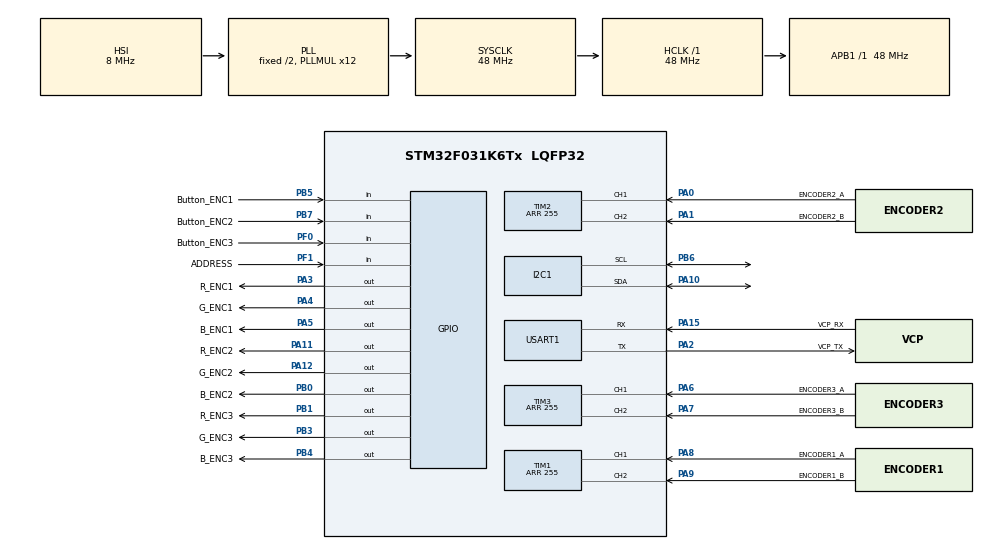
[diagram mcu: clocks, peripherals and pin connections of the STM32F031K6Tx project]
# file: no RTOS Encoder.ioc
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I2C1.Analog_Filter=I2C_ANALOGFILTER_DISABLE
I2C1.I2C_Fall_Time=10
I2C1.I2C_Rise_Time=10
I2C1.Timing=0x00201D2D
Mcu.Family=STM32F0
Mcu.Name=STM32F031K6Tx
Mcu.Package=LQFP32
NVIC.I2C1_IRQn=true\:0\:0\:false\:false\:true\:true\:true
NVIC.TIM14_IRQn=true\:0\:0\:false\:false\:true\:false\:true
NVIC.TimeBase=TIM14_IRQn
NVIC.TimeBaseIP=TIM14
PA0.GPIO_Label=ENCODER2_A
PA0.GPIO_PuPd=GPIO_PULLUP
PA0.Signal=S_TIM2_CH1_ETR
PA1.GPIO_Label=ENCODER2_B
PA1.GPIO_PuPd=GPIO_PULLUP
PA1.Signal=S_TIM2_CH2
PA10.Mode=I2C
PA10.Signal=I2C1_SDA
PA11.GPIO_Label=R_ENC2
PA11.Signal=GPIO_Output
PA12.GPIO_Label=G_ENC2
PA12.Signal=GPIO_Output
PA13.GPIO_Label=SWDIO
PA13.Mode=Serial_Wire
PA13.Signal=SYS_SWDIO
PA14.GPIO_Label=SWCLK
PA14.Mode=Serial_Wire
PA14.Signal=SYS_SWCLK
PA15.GPIO_Label=VCP_RX
PA15.Mode=Asynchronous
PA15.Signal=USART1_RX
PA2.GPIO_Label=VCP_TX
PA2.Mode=Asynchronous
PA2.Signal=USART1_TX
PA3.GPIO_Label=R_ENC1
PA3.Signal=GPIO_Output
PA4.GPIO_Label=G_ENC1
PA4.Signal=GPIO_Output
PA5.GPIO_Label=B_ENC1
PA5.Signal=GPIO_Output
PA6.GPIO_Label=ENCODER3_A
PA6.GPIO_PuPd=GPIO_PULLUP
PA6.Signal=S_TIM3_CH1
PA7.GPIO_Label=ENCODER3_B
PA7.GPIO_PuPd=GPIO_PULLUP
PA7.Signal=S_TIM3_CH2
PA8.GPIO_Label=ENCODER1_A
PA8.GPIO_PuPd=GPIO_PULLUP
PA8.Signal=S_TIM1_CH1
PA9.GPIO_Label=ENCODER1_B
PA9.GPIO_PuPd=GPIO_PULLUP
PA9.Signal=S_TIM1_CH2
PB0.GPIO_Label=B_ENC2
PB0.Signal=GPIO_Output
PB1.GPIO_Label=R_ENC3
PB1.Signal=GPIO_Output
PB3.GPIO_Label=G_ENC3
PB3.Signal=GPIO_Output
PB4.GPIO_Label=B_ENC3
PB4.Signal=GPIO_Output
PB5.GPIO_Label=Button_ENC1
PB5.Signal=GPIO_Input
PB6.Mode=I2C
PB6.Signal=I2C1_SCL
PB7.GPIO_Label=Button_ENC2
PB7.Signal=GPIO_Input
PF0-OSC_IN.GPIO_Label=Button_ENC3
PF0-OSC_IN.Signal=GPIO_Input
PF1-OSC_OUT.GPIO_Label=ADDRESS
PF1-OSC_OUT.Signal=GPIO_Input
ProjectManager.HeapSize=0x200
ProjectManager.StackSize=0x400
ProjectManager.TargetToolchain=SW4STM32
RCC.AHBFreq_Value=48000000
RCC.APB1Freq_Value=48000000
RCC.APB1TimFreq_Value=48000000
RCC.HCLKFreq_Value=48000000
RCC.PLLMUL=RCC_PLL_MUL12
RCC.SYSCLKFreq_VALUE=48000000
RCC.SYSCLKSource=RCC_SYSCLKSOURCE_PLLCLK
SH.S_TIM1_CH1.0=TIM1_CH1,Encoder_Interface
SH.S_TIM1_CH2.0=TIM1_CH2,Encoder_Interface
SH.S_TIM2_CH1_ETR.0=TIM2_CH1,Encoder_Interface
SH.S_TIM2_CH2.0=TIM2_CH2,Encoder_Interface
SH.S_TIM3_CH1.0=TIM3_CH1,Encoder_Interface
SH.S_TIM3_CH2.0=TIM3_CH2,Encoder_Interface
TIM1.EncoderMode=TIM_ENCODERMODE_TI12
TIM1.IC1Filter=0
TIM1.IC1Polarity=TIM_ICPOLARITY_FALLING
TIM1.IC2Filter=0
TIM1.IC2Polarity=TIM_ICPOLARITY_FALLING
TIM1.Period=255
TIM16.Period=10000
TIM16.Prescaler=48
TIM2.EncoderMode=TIM_ENCODERMODE_TI12
TIM2.IC1Filter=0
TIM2.IC1Polarity=TIM_ICPOLARITY_FALLING
TIM2.IC2Polarity=TIM_ICPOLARITY_FALLING
TIM2.Period=255
TIM3.IC1Filter=0
TIM3.IC1Polarity=TIM_ICPOLARITY_FALLING
TIM3.IC2Filter=0
TIM3.IC2Polarity=TIM_ICPOLARITY_FALLING
TIM3.Period=255
USART1.VirtualMode-Asynchronous=VM_ASYNC
VP_SYS_VS_tim14.Mode=TIM14
VP_TIM16_VS_ClockSourceINT.Mode=Enable_Timer
board=NUCLEO-F031K6

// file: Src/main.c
/* USER CODE BEGIN Header */
/**
  ******************************************************************************
  * @file           : main.c
  * @brief          : Main program body
  ******************************************************************************
  * @attention
  *
  * <h2><center>&copy; Copyright (c) 2019 STMicroelectronics.
  * All rights reserved.</center></h2>
  *
  * This software component is licensed by ST under BSD 3-Clause license,
  * the "License"; You may not use this file except in compliance with the
  * License. You may obtain a copy of the License at:
  *                        opensource.org/licenses/BSD-3-Clause
  *
  ******************************************************************************
  */
/* USER CODE END Header */

#include "main.h"

I2C_HandleTypeDef hi2c1;

TIM_HandleTypeDef htim1;
TIM_HandleTypeDef htim2;
TIM_HandleTypeDef htim3;
TIM_HandleTypeDef htim16;

UART_HandleTypeDef huart1;

void SystemClock_Config(void);
static void MX_GPIO_Init(void);
static void MX_I2C1_Init(void);
static void MX_TIM1_Init(void);
static void MX_TIM2_Init(void);
static void MX_TIM3_Init(void);
static void MX_USART1_UART_Init(void);
static void MX_TIM16_Init(void);

int main(void)
{

  /* MCU Configuration--------------------------------------------------------*/

  /* Reset of all peripherals, Initializes the Flash interface and the Systick. */
  HAL_Init();

  /* Configure the system clock */
  SystemClock_Config();

  /* Initialize all configured peripherals */
  MX_GPIO_Init();
  MX_I2C1_Init();
  MX_TIM1_Init();
  MX_TIM2_Init();
  MX_TIM3_Init();
  MX_USART1_UART_Init();
  MX_TIM16_Init();
  /* USER CODE BEGIN 2 */
  uint8_t aTxBuffer[] = "E";

  /* Buffer used for reception */
  uint8_t aRxBuffer[1];

  uint32_t Encoder_CODE;
  HAL_I2C_Slave_Receive_DMA(&hi2c1,aRxBuffer,1);
  HAL_I2C_Slave_Transmit_DMA(&hi2c1,aTxBuffer,1);
  /* USER CODE END 2 */

  /* Infinite loop */
  while (1)
  {

  }
}

void SystemClock_Config(void)
{
  RCC_OscInitTypeDef RCC_OscInitStruct = {0};
  RCC_ClkInitTypeDef RCC_ClkInitStruct = {0};
  RCC_PeriphCLKInitTypeDef PeriphClkInit = {0};

  /** Initializes the CPU, AHB and APB busses clocks
  */
  RCC_OscInitStruct.OscillatorType = RCC_OSCILLATORTYPE_HSI;
  RCC_OscInitStruct.HSIState = RCC_HSI_ON;
  RCC_OscInitStruct.HSICalibrationValue = RCC_HSICALIBRATION_DEFAULT;
  RCC_OscInitStruct.PLL.PLLState = RCC_PLL_ON;
  RCC_OscInitStruct.PLL.PLLSource = RCC_PLLSOURCE_HSI;
  RCC_OscInitStruct.PLL.PLLMUL = RCC_PLL_MUL12;
  RCC_OscInitStruct.PLL.PREDIV = RCC_PREDIV_DIV1;
  if (HAL_RCC_OscConfig(&RCC_OscInitStruct) != HAL_OK)
  {
    Error_Handler();
  }
  /** Initializes the CPU, AHB and APB busses clocks
  */
  RCC_ClkInitStruct.ClockType = RCC_CLOCKTYPE_HCLK|RCC_CLOCKTYPE_SYSCLK
                              |RCC_CLOCKTYPE_PCLK1;
  RCC_ClkInitStruct.SYSCLKSource = RCC_SYSCLKSOURCE_PLLCLK;
  RCC_ClkInitStruct.AHBCLKDivider = RCC_SYSCLK_DIV1;
  RCC_ClkInitStruct.APB1CLKDivider = RCC_HCLK_DIV1;

  if (HAL_RCC_ClockConfig(&RCC_ClkInitStruct, FLASH_LATENCY_1) != HAL_OK)
  {
    Error_Handler();
  }
  PeriphClkInit.PeriphClockSelection = RCC_PERIPHCLK_USART1|RCC_PERIPHCLK_I2C1;
  PeriphClkInit.Usart1ClockSelection = RCC_USART1CLKSOURCE_PCLK1;
  PeriphClkInit.I2c1ClockSelection = RCC_I2C1CLKSOURCE_HSI;
  if (HAL_RCCEx_PeriphCLKConfig(&PeriphClkInit) != HAL_OK)
  {
    Error_Handler();
  }
}

static void MX_I2C1_Init(void)
{

  hi2c1.Instance = I2C1;
  hi2c1.Init.Timing = 0x00201D2D;
  hi2c1.Init.OwnAddress1 = 0;
  hi2c1.Init.AddressingMode = I2C_ADDRESSINGMODE_7BIT;
  hi2c1.Init.DualAddressMode = I2C_DUALADDRESS_DISABLE;
  hi2c1.Init.OwnAddress2 = 0;
  hi2c1.Init.OwnAddress2Masks = I2C_OA2_NOMASK;
  hi2c1.Init.GeneralCallMode = I2C_GENERALCALL_DISABLE;
  hi2c1.Init.NoStretchMode = I2C_NOSTRETCH_DISABLE;
  if (HAL_I2C_Init(&hi2c1) != HAL_OK)
  {
    Error_Handler();
  }
  /** Configure Analogue filter
  */
  if (HAL_I2CEx_ConfigAnalogFilter(&hi2c1, I2C_ANALOGFILTER_DISABLE) != HAL_OK)
  {
    Error_Handler();
  }
  /** Configure Digital filter
  */
  if (HAL_I2CEx_ConfigDigitalFilter(&hi2c1, 0) != HAL_OK)
  {
    Error_Handler();
  }

}

static void MX_TIM1_Init(void)
{

  TIM_Encoder_InitTypeDef sConfig = {0};
  TIM_MasterConfigTypeDef sMasterConfig = {0};

  htim1.Instance = TIM1;
  htim1.Init.Prescaler = 0;
  htim1.Init.CounterMode = TIM_COUNTERMODE_UP;
  htim1.Init.Period = 255;
  htim1.Init.ClockDivision = TIM_CLOCKDIVISION_DIV1;
  htim1.Init.RepetitionCounter = 0;
  htim1.Init.AutoReloadPreload = TIM_AUTORELOAD_PRELOAD_DISABLE;
  sConfig.EncoderMode = TIM_ENCODERMODE_TI12;
  sConfig.IC1Polarity = TIM_ICPOLARITY_FALLING;
  sConfig.IC1Selection = TIM_ICSELECTION_DIRECTTI;
  sConfig.IC1Prescaler = TIM_ICPSC_DIV1;
  sConfig.IC1Filter = 0;
  sConfig.IC2Polarity = TIM_ICPOLARITY_FALLING;
  sConfig.IC2Selection = TIM_ICSELECTION_DIRECTTI;
  sConfig.IC2Prescaler = TIM_ICPSC_DIV1;
  sConfig.IC2Filter = 0;
  if (HAL_TIM_Encoder_Init(&htim1, &sConfig) != HAL_OK)
  {
    Error_Handler();
  }
  sMasterConfig.MasterOutputTrigger = TIM_TRGO_RESET;
  sMasterConfig.MasterSlaveMode = TIM_MASTERSLAVEMODE_DISABLE;
  if (HAL_TIMEx_MasterConfigSynchronization(&htim1, &sMasterConfig) != HAL_OK)
  {
    Error_Handler();
  }

}

static void MX_TIM2_Init(void)
{

  TIM_Encoder_InitTypeDef sConfig = {0};
  TIM_MasterConfigTypeDef sMasterConfig = {0};

  htim2.Instance = TIM2;
  htim2.Init.Prescaler = 0;
  htim2.Init.CounterMode = TIM_COUNTERMODE_UP;
  htim2.Init.Period = 255;
  htim2.Init.ClockDivision = TIM_CLOCKDIVISION_DIV1;
  htim2.Init.AutoReloadPreload = TIM_AUTORELOAD_PRELOAD_DISABLE;
  sConfig.EncoderMode = TIM_ENCODERMODE_TI12;
  sConfig.IC1Polarity = TIM_ICPOLARITY_FALLING;
  sConfig.IC1Selection = TIM_ICSELECTION_DIRECTTI;
  sConfig.IC1Prescaler = TIM_ICPSC_DIV1;
  sConfig.IC1Filter = 0;
  sConfig.IC2Polarity = TIM_ICPOLARITY_FALLING;
  sConfig.IC2Selection = TIM_ICSELECTION_DIRECTTI;
  sConfig.IC2Prescaler = TIM_ICPSC_DIV1;
  sConfig.IC2Filter = 0;
  if (HAL_TIM_Encoder_Init(&htim2, &sConfig) != HAL_OK)
  {
    Error_Handler();
  }
  sMasterConfig.MasterOutputTrigger = TIM_TRGO_RESET;
  sMasterConfig.MasterSlaveMode = TIM_MASTERSLAVEMODE_DISABLE;
  if (HAL_TIMEx_MasterConfigSynchronization(&htim2, &sMasterConfig) != HAL_OK)
  {
    Error_Handler();
  }

}

static void MX_TIM3_Init(void)
{

  TIM_Encoder_InitTypeDef sConfig = {0};
  TIM_MasterConfigTypeDef sMasterConfig = {0};

  htim3.Instance = TIM3;
  htim3.Init.Prescaler = 0;
  htim3.Init.CounterMode = TIM_COUNTERMODE_UP;
  htim3.Init.Period = 255;
  htim3.Init.ClockDivision = TIM_CLOCKDIVISION_DIV1;
  htim3.Init.AutoReloadPreload = TIM_AUTORELOAD_PRELOAD_DISABLE;
  sConfig.EncoderMode = TIM_ENCODERMODE_TI1;
  sConfig.IC1Polarity = TIM_ICPOLARITY_FALLING;
  sConfig.IC1Selection = TIM_ICSELECTION_DIRECTTI;
  sConfig.IC1Prescaler = TIM_ICPSC_DIV1;
  sConfig.IC1Filter = 0;
  sConfig.IC2Polarity = TIM_ICPOLARITY_FALLING;
  sConfig.IC2Selection = TIM_ICSELECTION_DIRECTTI;
  sConfig.IC2Prescaler = TIM_ICPSC_DIV1;
  sConfig.IC2Filter = 0;
  if (HAL_TIM_Encoder_Init(&htim3, &sConfig) != HAL_OK)
  {
    Error_Handler();
  }
  sMasterConfig.MasterOutputTrigger = TIM_TRGO_RESET;
  sMasterConfig.MasterSlaveMode = TIM_MASTERSLAVEMODE_DISABLE;
  if (HAL_TIMEx_MasterConfigSynchronization(&htim3, &sMasterConfig) != HAL_OK)
  {
    Error_Handler();
  }

}

static void MX_TIM16_Init(void)
{

  htim16.Instance = TIM16;
  htim16.Init.Prescaler = 48;
  htim16.Init.CounterMode = TIM_COUNTERMODE_UP;
  htim16.Init.Period = 10000;
  htim16.Init.ClockDivision = TIM_CLOCKDIVISION_DIV1;
  htim16.Init.RepetitionCounter = 0;
  htim16.Init.AutoReloadPreload = TIM_AUTORELOAD_PRELOAD_DISABLE;
  if (HAL_TIM_Base_Init(&htim16) != HAL_OK)
  {
    Error_Handler();
  }

}

static void MX_USART1_UART_Init(void)
{

  huart1.Instance = USART1;
  huart1.Init.BaudRate = 38400;
  huart1.Init.WordLength = UART_WORDLENGTH_8B;
  huart1.Init.StopBits = UART_STOPBITS_1;
  huart1.Init.Parity = UART_PARITY_NONE;
  huart1.Init.Mode = UART_MODE_TX_RX;
  huart1.Init.HwFlowCtl = UART_HWCONTROL_NONE;
  huart1.Init.OverSampling = UART_OVERSAMPLING_16;
  huart1.Init.OneBitSampling = UART_ONE_BIT_SAMPLE_DISABLE;
  huart1.AdvancedInit.AdvFeatureInit = UART_ADVFEATURE_NO_INIT;
  if (HAL_UART_Init(&huart1) != HAL_OK)
  {
    Error_Handler();
  }

}

static void MX_GPIO_Init(void)
{
  GPIO_InitTypeDef GPIO_InitStruct = {0};

  /* GPIO Ports Clock Enable */
  __HAL_RCC_GPIOF_CLK_ENABLE();
  __HAL_RCC_GPIOA_CLK_ENABLE();
  __HAL_RCC_GPIOB_CLK_ENABLE();

  /*Configure GPIO pin Output Level */
  HAL_GPIO_WritePin(GPIOA, R_ENC1_Pin|G_ENC1_Pin|B_ENC1_Pin|R_ENC2_Pin
                          |G_ENC2_Pin, GPIO_PIN_RESET);

  /*Configure GPIO pin Output Level */
  HAL_GPIO_WritePin(GPIOB, B_ENC2_Pin|R_ENC3_Pin|G_ENC3_Pin|B_ENC3_Pin, GPIO_PIN_RESET);

  /*Configure GPIO pins : Button_ENC3_Pin ADDRESS_Pin */
  GPIO_InitStruct.Pin = Button_ENC3_Pin|ADDRESS_Pin;
  GPIO_InitStruct.Mode = GPIO_MODE_INPUT;
  GPIO_InitStruct.Pull = GPIO_NOPULL;
  HAL_GPIO_Init(GPIOF, &GPIO_InitStruct);

  /*Configure GPIO pins : R_ENC1_Pin G_ENC1_Pin B_ENC1_Pin R_ENC2_Pin
                           G_ENC2_Pin */
  GPIO_InitStruct.Pin = R_ENC1_Pin|G_ENC1_Pin|B_ENC1_Pin|R_ENC2_Pin
                          |G_ENC2_Pin;
  GPIO_InitStruct.Mode = GPIO_MODE_OUTPUT_PP;
  GPIO_InitStruct.Pull = GPIO_NOPULL;
  GPIO_InitStruct.Speed = GPIO_SPEED_FREQ_LOW;
  HAL_GPIO_Init(GPIOA, &GPIO_InitStruct);

  /*Configure GPIO pins : B_ENC2_Pin R_ENC3_Pin G_ENC3_Pin B_ENC3_Pin */
  GPIO_InitStruct.Pin = B_ENC2_Pin|R_ENC3_Pin|G_ENC3_Pin|B_ENC3_Pin;
  GPIO_InitStruct.Mode = GPIO_MODE_OUTPUT_PP;
  GPIO_InitStruct.Pull = GPIO_NOPULL;
  GPIO_InitStruct.Speed = GPIO_SPEED_FREQ_LOW;
  HAL_GPIO_Init(GPIOB, &GPIO_InitStruct);

  /*Configure GPIO pins : Button_ENC1_Pin Button_ENC2_Pin */
  GPIO_InitStruct.Pin = Button_ENC1_Pin|Button_ENC2_Pin;
  GPIO_InitStruct.Mode = GPIO_MODE_INPUT;
  GPIO_InitStruct.Pull = GPIO_NOPULL;
  HAL_GPIO_Init(GPIOB, &GPIO_InitStruct);

}

void HAL_TIM_PeriodElapsedCallback(TIM_HandleTypeDef *htim)
{
  if (htim->Instance == TIM14) {
    HAL_IncTick();
  }
}

void Error_Handler(void)
{
}

/************************ (C) COPYRIGHT STMicroelectronics *****END OF FILE****/
